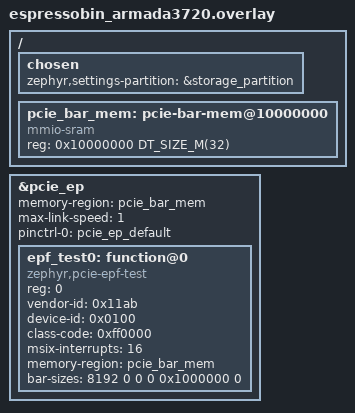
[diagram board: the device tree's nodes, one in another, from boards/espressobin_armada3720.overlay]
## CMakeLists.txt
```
# SPDX-License-Identifier: Apache-2.0

cmake_minimum_required(VERSION 3.20.0)
find_package(Zephyr REQUIRED HINTS $ENV{ZEPHYR_BASE})
project(pcie_epf_test)

target_sources(app PRIVATE src/main.c)
```

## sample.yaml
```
sample:
  name: PCIe endpoint test function
  description: Linux pci_endpoint_test compatible PCIe endpoint
common:
  tags:
    - pcie
    - drivers
  harness: console
  harness_config:
    type: one_line
    regex:
      - "test regs in BAR"
tests:
  sample.drivers.pcie.endpoint.epf_test:
    platform_allow:
      - espressobin/armada3720
      - espressobin/armada3720/smp
    integration_platforms:
      - espressobin/armada3720
    build_only: true
```

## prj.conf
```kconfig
CONFIG_PCIE_ENDPOINT=y
CONFIG_LOG=y
CONFIG_PCIE_EP_LOG_LEVEL_INF=y
CONFIG_SHELL=y
```

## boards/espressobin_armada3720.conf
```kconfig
# No CONFIG_GPIO: a PERST# GPIO (perst-gpios) needs it, but the GPIO
# driver is a suspect of the SD image boot loop, so it stays off until
# that is understood.
# Outbound window (16 MiB) and BAR carveout are mapped at run time
CONFIG_KERNEL_VM_SIZE=0x8000000
CONFIG_MAX_XLAT_TABLES=48
# Bring-up: init checkpoints and logs as they happen
CONFIG_PCIE_EPC_AARDVARK_TRACE_INIT=y
CONFIG_LOG_MODE_IMMEDIATE=y
# printk straight to the UART: the shell log backend starts after the
# drivers, early output would be lost
CONFIG_LOG_PRINTK=n
CONFIG_SHELL_LOG_BACKEND=n
CONFIG_LOG_BACKEND_UART=y
# Scripted from the host over the serial console: room for the probe
# commands, plain output, reboot from the shell
CONFIG_SHELL_STACK_SIZE=8192
CONFIG_SHELL_VT100_COLORS=n
CONFIG_KERNEL_SHELL=y
CONFIG_REBOOT=y
# Update the image over the console (YMODEM), no network in this image
CONFIG_SPI=y
CONFIG_FLASH=y
CONFIG_FLASH_MAP=y
CONFIG_FLASH_SHELL=y
CONFIG_FWUPDATE=y
# devmem: poke SoC registers outside the controller (IO decode windows)
CONFIG_DEVMEM_SHELL=y
# Device Serial Number: generated on the first boot, kept in settings
# (NVS in the zephyr-storage partition, shared with the netshell)
CONFIG_SETTINGS=y
CONFIG_SETTINGS_NVS=y
CONFIG_NVS=y
CONFIG_TEST_RANDOM_GENERATOR=y
CONFIG_PCIE_EPC_DSN_SETTINGS=y
```

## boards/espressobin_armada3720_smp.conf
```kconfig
# No CONFIG_GPIO: a PERST# GPIO (perst-gpios) needs it, but the GPIO
# driver is a suspect of the SD image boot loop, so it stays off until
# that is understood.
# Outbound window (16 MiB) and BAR carveout are mapped at run time
CONFIG_KERNEL_VM_SIZE=0x4000000
CONFIG_MAX_XLAT_TABLES=32
# Bring-up: init checkpoints and logs as they happen
CONFIG_PCIE_EPC_AARDVARK_TRACE_INIT=y
CONFIG_LOG_MODE_IMMEDIATE=y
# printk straight to the UART: the shell log backend starts after the
# drivers, early output would be lost
CONFIG_LOG_PRINTK=n
CONFIG_SHELL_LOG_BACKEND=n
CONFIG_LOG_BACKEND_UART=y
```

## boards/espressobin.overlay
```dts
/*
 * ESPRESSObin: the Armada 3720 PCIe controller as endpoint on the
 * mini-PCIe slot.
 *
 * The slot is wired as a host slot (SoC TX on PERp/n 25/23, SoC RX on
 * PETp/n 33/31), so the link needs a crossover cable: host TX onto
 * PETp/n, PERp/n to host RX, ground. REFCLK and the supplies must NOT
 * be connected (ESPRESSObin wiki "Enabling ESPRESSObin board as PCIe
 * Endpoint"): both sides run on their own reference clock. PERST# from
 * the host onto pin 22 (PCA9306 to MPP2_3) is optional.
 */

#include <mem.h>

/ {
	/* BAR backing store in DDR, outside the Zephyr image */
	pcie_bar_mem: memory@10000000 {
		compatible = "mmio-sram";
		reg = <0x10000000 DT_SIZE_M(2)>;
	};
};

&pcie_ep {
	status = "okay";
	pinctrl-0 = <&pcie_ep_default>;
	pinctrl-names = "default";
	/*
	 * PERST# input; needs CONFIG_GPIO=y and the SB GPIO controller:
	 * perst-gpios = <&gpiosb 3 GPIO_ACTIVE_LOW>;
	 */

	epf_test0: function@0 {
		compatible = "zephyr,pcie-epf-test";
		reg = <0>;
		/*
		 * Marvell / A3720 default device ID, not in the pci_endpoint_test
		 * ID table: on the host
		 * echo "11ab 0100" > /sys/bus/pci/drivers/pci-endpoint-test/new_id
		 */
		vendor-id = <0x11ab>;
		device-id = <0x0100>;
		class-code = <0xff0000>;
		memory-region = <&pcie_bar_mem>;
		/*
		 * Hardware BARs: 0 (64-bit), 2 (I/O, reserved), 4 (64-bit);
		 * BAR3 reads as unused, the driver keeps it offered.
		 */
		bar-sizes = <512 0 0 16384 131072 0>;
	};
};
```

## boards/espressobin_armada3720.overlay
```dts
/*
 * ESPRESSObin: the Armada 3720 PCIe controller as endpoint on the
 * mini-PCIe slot.
 *
 * The slot is wired as a host slot (SoC TX on PERp/n 25/23, SoC RX on
 * PETp/n 33/31), so the link needs a crossover cable: host TX onto
 * PETp/n, PERp/n to host RX, ground. REFCLK and the supplies must NOT
 * be connected (ESPRESSObin wiki "Enabling ESPRESSObin board as PCIe
 * Endpoint"): both sides run on their own reference clock. PERST# from
 * the host onto pin 22 (PCA9306 to MPP2_3) is optional.
 */

#include <mem.h>

/ {
	chosen {
		zephyr,settings-partition = &storage_partition;
	};

	/*
	 * BAR backing store, outside Zephyr's RAM (ddr0 = 0..64 MiB) and
	 * TF-A (0x04000000..): nothing else uses it. Each BAR's inbound
	 * translation places it here, aligned to the BAR size (BAR0 8 KiB
	 * at +0, BAR4 16 MiB at +16 MiB), and the PCIe IO decode
	 * window is limited to it, so the host sees nothing else of DDR.
	 */
	pcie_bar_mem: pcie-bar-mem@10000000 {
		compatible = "mmio-sram";
		reg = <0x10000000 DT_SIZE_M(32)>;
	};
};


&pcie_ep {
	status = "okay";
	memory-region = <&pcie_bar_mem>;
	/*
	 * Gen1 for now: at Gen2 the crossover link shows RxErr / BadTLP /
	 * replay timeouts in both directions and drops into Recovery now and
	 * then. Remove (or 2) for 5 GT/s.
	 */
	max-link-speed = <1>;
	pinctrl-0 = <&pcie_ep_default>;
	pinctrl-names = "default";
	/*
	 * PERST# input; needs CONFIG_GPIO=y and the SB GPIO controller:
	 * perst-gpios = <&gpiosb 3 GPIO_ACTIVE_LOW>;
	 */

	epf_test0: function@0 {
		compatible = "zephyr,pcie-epf-test";
		reg = <0>;
		/*
		 * Marvell / A3720 default device ID, not in the pci_endpoint_test
		 * ID table: on the host
		 * echo "11ab 0100" > /sys/bus/pci/drivers/pci-endpoint-test/new_id
		 */
		vendor-id = <0x11ab>;
		device-id = <0x0100>;
		class-code = <0xff0000>;
		/* MSI-X table at register BAR + 0x40, PBA after it (16 x 16 B) */
		msix-interrupts = <16>;
		memory-region = <&pcie_bar_mem>;
		/*
		 * BAR0 and BAR4, 64-bit memory, sized through the LMI BAR
		 * configuration (powers of two); BAR2 (I/O) is switched off.
		 * BAR0 gets the registers, MSI-X table and DSN mailbox.
		 */
		bar-sizes = <8192 0 0 0 0x1000000 0>;
	};
};
```

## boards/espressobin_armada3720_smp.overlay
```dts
#include "espressobin.overlay"
```

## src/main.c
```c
/*
 * Copyright (c) 2026 Jiri Kastner
 *
 * SPDX-License-Identifier: Apache-2.0
 *
 * Everything happens in the EPC/EPF drivers; main() only reports link state
 * and offers a couple of shell commands for bring-up.
 */

#include <stdlib.h>

#include <zephyr/kernel.h>
#include <zephyr/shell/shell.h>
#include <zephyr/drivers/pcie/endpoint/pcie_epc.h>

#define EPC_NODE DT_PARENT(DT_COMPAT_GET_ANY_STATUS_OKAY(zephyr_pcie_epf_test))

static const struct device *const epc = DEVICE_DT_GET(EPC_NODE);

static int cmd_status(const struct shell *sh, size_t argc, char **argv)
{
	uint32_t v;

	ARG_UNUSED(argc);
	ARG_UNUSED(argv);

	shell_print(sh, "%s: link %s", epc->name, pcie_epc_link_up(epc) ? "up" : "down");
	for (uint32_t off = 0; off < 0x40; off += 4) {
		if (pcie_epc_cfg_read(epc, 0, off, &v) == 0) {
			shell_print(sh, "  cfg[0x%02x] = 0x%08x", off, v);
		}
	}
	return 0;
}

static int cmd_msi(const struct shell *sh, size_t argc, char **argv)
{
	int n = argc > 1 ? atoi(argv[1]) : 1;
	int ret = pcie_epc_raise_irq(epc, 0, PCIE_EPC_IRQ_MSI, n);

	shell_print(sh, "raise MSI %d: %d (host enabled %d vectors)", n, ret,
		    pcie_epc_get_msi(epc, 0));
	return 0;
}

static int cmd_start(const struct shell *sh, size_t argc, char **argv)
{
	ARG_UNUSED(argc);
	ARG_UNUSED(argv);
	shell_print(sh, "start: %d", pcie_epc_start(epc));
	return 0;
}

SHELL_STATIC_SUBCMD_SET_CREATE(sub_ep,
	SHELL_CMD(status, NULL, "Link state and config header", cmd_status),
	SHELL_CMD_ARG(msi, NULL, "Raise MSI <n>", cmd_msi, 1, 1),
	SHELL_CMD(start, NULL, "Start link training", cmd_start),
	SHELL_SUBCMD_SET_END);
SHELL_CMD_REGISTER(pcie_ep, &sub_ep, "PCIe endpoint", NULL);

int main(void)
{
	bool last = false;

	if (!device_is_ready(epc)) {
		printk("%s not ready\n", epc->name);
		return 0;
	}

	for (;;) {
		bool up = pcie_epc_link_up(epc);

		if (up != last) {
			printk("%s: link %s\n", epc->name, up ? "up" : "down");
			last = up;
		}
		k_sleep(K_MSEC(500));
	}
	return 0;
}
```
